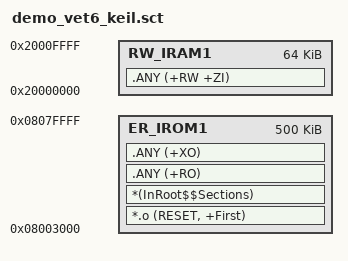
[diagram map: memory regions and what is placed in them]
; *************************************************************
; *** Scatter-Loading Description File generated by uVision ***
; *************************************************************

;如果不用bootloader就是下面这个地址
;LR_IROM1 0x08000000 0x0007D000  {    ; load region size_region
;  ER_IROM1 0x08000000 0x0007D000  {  ; load address = execution address

;用bootloader就得同时设置 system_stm32f1xx.c 中的 VECT_TAB_OFFSET 宏定义
LR_IROM1 0x08003000 0x0007D000  {    ; load region size_region
  ER_IROM1 0x08003000 0x0007D000  {  ; load address = execution address
   *.o (RESET, +First)
   *(InRoot$$Sections)
   .ANY (+RO)
   .ANY (+XO)
  }
  RW_IRAM1 0x20000000 0x00010000  {  ; RW data
   .ANY (+RW +ZI)
  }
}

